# MDR1986VK01 register map
File version: 1.0.2
Registers are 32-bit, read-write, no defined reset value unless marked. A register's access mark holds for its fields unless they carry their own. Offsets are from the block's base; [hi:lo] are bit positions; {n}, {i} and the like mark numbered series; 'fields as' and 'values as' point back to an identical list.

## MDR_USB — MDR_USB description
Base 0x21010000
0x00 FADDR 8-bit — FADDR description
  [6:0] FADDR
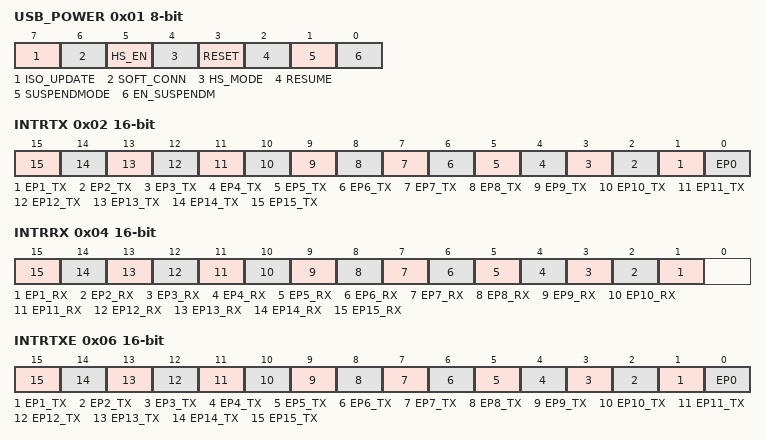
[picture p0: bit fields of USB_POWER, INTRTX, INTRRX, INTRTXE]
0x01 USB_POWER 8-bit — USB_POWER description
  [7] ISO_UPDATE — ISO_UPDATE description
  [6] SOFT_CONN — SOFT_CONN description
  [5] HS_EN — HS_EN description
  [4] HS_MODE — HS_MODE description
  [3] RESET — RESET description
  [2] RESUME — RESUME description
  [1] SUSPENDMODE — SUSPENDMODE description
  [0] EN_SUSPENDM — EN_SUSPENDM description
0x02 INTRTX 16-bit — INTRTX description
  [n] EP{n}_TX (n=1..15) — EP{n}_TX description
  [0] EP0 — EP0 description
0x04 INTRRX 16-bit — INTRRX description
  [n] EP{n}_RX (n=1..15) — EP{n}_RX description
0x06 INTRTXE 16-bit — INTRTXE description
  fields as INTRTX
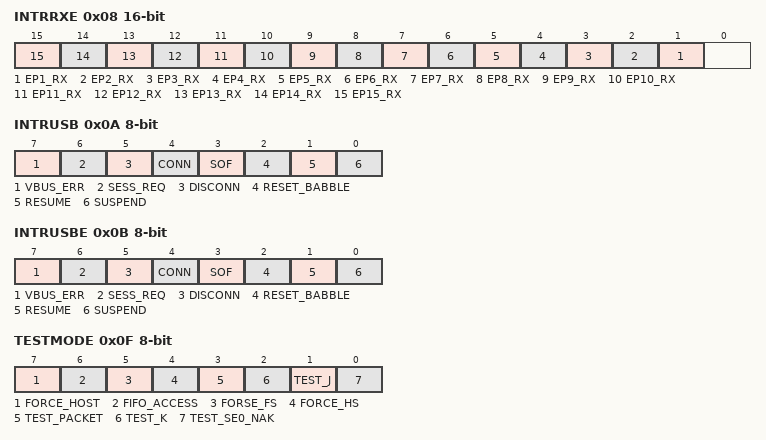
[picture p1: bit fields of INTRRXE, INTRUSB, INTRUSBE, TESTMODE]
0x08 INTRRXE 16-bit — INTRRXE description
  [n] EP{n}_RX (n=1..15) — EP{n}_RX description
0x0A INTRUSB 8-bit — INTRUSB description
  [7] VBUS_ERR — VBUS_ERR description
  [6] SESS_REQ — SESS_REQ description
  [5] DISCONN — DISCONN description
  [4] CONN — CONN description
  [3] SOF — SOF description
  [2] RESET_BABBLE — RESET_BABBLE description
  [1] RESUME — RESUME description
  [0] SUSPEND — SUSPEND description
0x0B INTRUSBE 8-bit — INTRUSBE description
  fields as INTRUSB
0x0C FRAME 16-bit — FRAME description
  [10:0] FRAME
0x0E INDEX 8-bit — INDEX description
  [3:0] INDEX
0x0F TESTMODE 8-bit — TESTMODE description
  [7] FORCE_HOST — FORCE_HOST description
  [6] FIFO_ACCESS — FIFO_ACCESS description
  [5] FORSE_FS — FORSE_FS description
  [4] FORCE_HS — FORCE_HS description
  [3] TEST_PACKET — TEST_PACKET description
  [2] TEST_K — TEST_K description
  [1] TEST_J — TEST_J description
  [0] TEST_SE0_NAK — TEST_SE0_NAK description
0x10 TXMAXP 16-bit — TXMAXP description
  [10:0] TXMAXP
0x12 CSR0_TXCSR 16-bit — CSR0_TXCSR description
0x14 RXMAXP 16-bit — RXMAXP description
  [10:0] RXMAXP
0x16 RXCSR 16-bit — RXCSR description
0x18 COUNT0_RXCOUNT 16-bit — COUNT0_RXCOUNT description
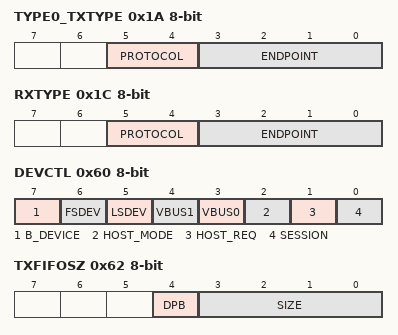
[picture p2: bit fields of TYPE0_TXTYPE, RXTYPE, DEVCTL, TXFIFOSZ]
0x1A TYPE0_TXTYPE 8-bit — TYPE0_TXTYPE description
  [5:4] PROTOCOL — PROTOCOL description
  [3:0] ENDPOINT — ENDPOINT description
0x1B NAKLIMIT0_TXINTERVAL 8-bit — NAKLIMIT0_TXINTERVAL description
0x1C RXTYPE 8-bit — RXTYPE description
  fields as TYPE0_TXTYPE
0x1D RXINTERVAL 8-bit — RXINTERVAL description
0x1F CONFIGDATA_FIFOSIZE 8-bit — CONFIGDATA_FIFOSIZE description
{0x20+4i} FIFO{i} (i=0..3) — FIFO{i} description
0x60 DEVCTL 8-bit — DEVCTL description
  [7] B_DEVICE — B_DEVICE description
  [6] FSDEV — FSDEV description
  [5] LSDEV — LSDEV description
  [4] VBUS1 — VBUS1 description
  [3] VBUS0 — VBUS0 description
  [2] HOST_MODE — HOST_MODE description
  [1] HOST_REQ — HOST_REQ description
  [0] SESSION — SESSION description
0x62 TXFIFOSZ 8-bit — TXFIFOSZ description
  [4] DPB — DPB description
  [3:0] SIZE — SIZE description
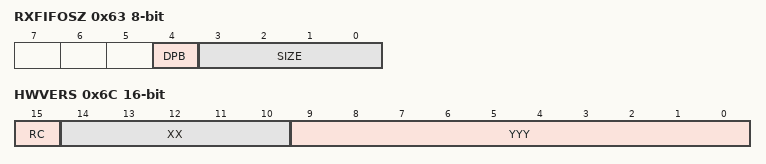
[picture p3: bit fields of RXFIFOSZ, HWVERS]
0x63 RXFIFOSZ 8-bit — RXFIFOSZ description
  [4] DPB — DPB description
  [3:0] SIZE — SIZE description
0x64 TXFIFOADD 16-bit — TXFIFOADD description
0x66 RXFIFOADD 16-bit — RXFIFOADD description
0x6C HWVERS 16-bit — HWVERS description
  [15] RC — RC description
  [14:10] XX — XX description
  [9:0] YYY — YYY description

## MDR_USB_RAM — MDR_USB_RAM description
Base 0x40093000
0x00 USB_RAM_CNTR — USB_RAM_CNTR description
0x04 USB_M31_CNTR — USB_M31_CNTR description

## MDR_USB_TAR0 — MDR_USB_TAR0 description
Base 0x2101007C
0x00 TX_FUNC_ADDR_T0 8-bit — TX_FUNC_ADDR_T0 description
0x02 TX_HUD_ADDR_T0 8-bit — TX_HUD_ADDR_T0 description
0x03 TX_HUD_PORT_T0 8-bit — TX_HUD_PORT_T0 description

## MDR_USB_TAR1 — MDR_USB_TAR1 description
Base 0x21010084
0x00 TX_FUNC_ADDR_T1 8-bit — TX_FUNC_ADDR_T1 description
0x02 TX_HUD_ADDR_T1 8-bit — TX_HUD_ADDR_T1 description
0x03 TX_HUD_PORT_T1 8-bit — TX_HUD_PORT_T1 description
0x04 RX_FUNC_ADDR_T1 8-bit — RX_FUNC_ADDR_T1 description
0x06 RX_HUD_ADDR_T1 8-bit — RX_HUD_ADDR_T1 description
0x07 RX_HUD_PORT_T1 8-bit — RX_HUD_PORT_T1 description
